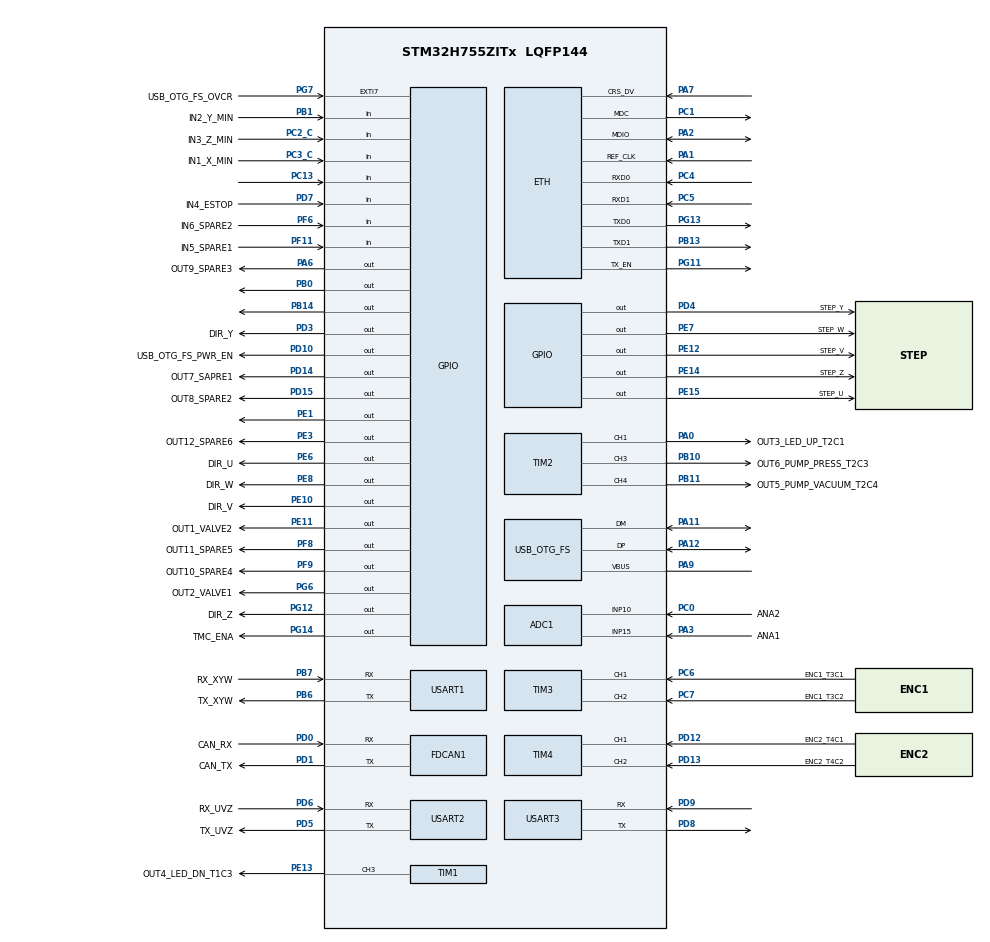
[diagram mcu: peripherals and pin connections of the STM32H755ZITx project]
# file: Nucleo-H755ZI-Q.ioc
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ADC1.Channel-0\#ChannelRegularConversion=ADC_CHANNEL_10
ADC1.NbrOfConversionFlag=1
ADC1.OffsetNumber-0\#ChannelRegularConversion=ADC_OFFSET_NONE
ADC1.OffsetSignedSaturation-0\#ChannelRegularConversion=DISABLE
ADC1.Rank-0\#ChannelRegularConversion=1
ADC1.SamplingTime-0\#ChannelRegularConversion=ADC_SAMPLETIME_1CYCLE_5
ADC1.master=1
CortexM4.IPs=FATFS_M4\:I,FREERTOS_M4\:I,IWDG2\:I,RCC,WWDG2\:I,DMA,BDMA,MDMA,NVIC2\:I,DEBUG,PDM2PCM_M4\:I,PWR,RESMGR_UTILITY,SYS_M4\:I,USB_DEVICE_M4\:I,USB_HOST_M4\:I,CORTEX_M4\:I,GPIO,OPENAMP_M4\:I,VREFBUF,NUCLEO-H755ZI-Q
CortexM7.IPs=FATFS_M7\:I,FREERTOS_M7\:I,IWDG1\:I,RCC\:I,WWDG1\:I,DMA\:I,BDMA\:I,MDMA\:I,NVIC1\:I,ETH\:I,USART3\:I,SYS\:I,CORTEX_M7\:I,DEBUG\:I,PDM2PCM_M7\:I,PWR\:I,RESMGR_UTILITY\:I,USB_DEVICE_M7\:I,USB_HOST_M7\:I,GPIO\:I,OPENAMP_M7\:I,VREFBUF\:I,NUCLEO-H755ZI-Q\:I,TIM1\:I,ADC3\:I,USB_OTG_FS\:I,LWIP\:I,TIM17\:I,FDCAN1\:I,USART2\:I,ADC1\:I,USART1\:I,TIM2\:I,TIM3\:I,TIM4\:I
CortexM7.Pins=PE3,PE6,PC13,PF6,PF8,PF9,PC2_C,PC3_C,PA6,PB1,PF11,PE7,PE8,PE10,PE11,PE12,PE14,PE15,PB14,PD10,PD14,PD15,PG6,PG7,PD3,PD4,PD7,PG12,PG14,PE1
ETH.MediaInterface=HAL_ETH_RMII_MODE
FDCAN1.CalculateBaudRateNominal=1000000
FDCAN1.CalculateTimeBitNominal=1000
FDCAN1.CalculateTimeQuantumNominal=200.0
FREERTOS_M7.Tasks01=defaultTask,24,512,StartDefaultTask,Default,NULL,Dynamic,NULL,NULL
FREERTOS_M7.configENABLE_FPU=1
FREERTOS_M7.configMINIMAL_STACK_SIZE=512
FREERTOS_M7.configUSE_NEWLIB_REENTRANT=1
LWIP.BSP.number=1
LWIP.Version=v2.1.2_Cube
LWIP0.BSP.STBoard=false
LWIP0.BSP.api=BSP_COMPONENT_DRIVER
LWIP0.BSP.component=LAN8742
LWIP0.BSP.instance=LAN8742
LWIP0.BSP.name=Driver_PHY
LWIP0.BSP.semaphore=S_LAN8742
LWIP0.BSP.solution=LAN8742
Mcu.Family=STM32H7
Mcu.Name=STM32H755ZITx
Mcu.Package=LQFP144
NUCLEO-H755ZI-Q.Bsp_Common_DEMO=true
NUCLEO-H755ZI-Q.LD1=true
NVIC1.ETH_IRQn=true\:5\:0\:false\:false\:true\:true\:true\:true\:true
NVIC1.OTG_FS_IRQn=true\:5\:0\:false\:false\:true\:true\:false\:true\:true
NVIC1.PriorityGroup=NVIC_PRIORITYGROUP_4
NVIC1.TIM17_IRQn=true\:15\:0\:false\:false\:true\:false\:false\:true\:true
NVIC1.TimeBase=TIM17_IRQn
NVIC1.TimeBaseIP=TIM17
NVIC2.PriorityGroup=NVIC_PRIORITYGROUP_4
PA0.GPIO_Label=OUT3_LED_UP_T2C1
PA0.PinAttribute=CortexM7
PA0.Signal=S_TIM2_CH1_ETR
PA1.Mode=RMII
PA1.PinAttribute=CortexM7
PA1.Signal=ETH_REF_CLK
PA11.Mode=Device_Only
PA11.PinAttribute=CortexM7
PA11.Signal=USB_OTG_FS_DM
PA12.Mode=Device_Only
PA12.PinAttribute=CortexM7
PA12.Signal=USB_OTG_FS_DP
PA2.Mode=RMII
PA2.PinAttribute=CortexM7
PA2.Signal=ETH_MDIO
PA3.GPIO_Label=ANA1
PA3.PinAttribute=CortexM7
PA3.Signal=ADCx_INP15
PA6.GPIO_Label=OUT9_SPARE3
PA6.PinAttribute=CortexM7
PA6.Signal=GPIO_Output
PA7.Mode=RMII
PA7.PinAttribute=CortexM7
PA7.Signal=ETH_CRS_DV
PA8.PinAttribute=CortexM7
PA8.Signal=USB_OTG_FS_SOF
PA9.Mode=Activate_VBUS
PA9.PinAttribute=CortexM7
PA9.Signal=USB_OTG_FS_VBUS
PB0.Signal=GPIO_Output
PB1.GPIO_Label=IN2_Y_MIN
PB1.PinAttribute=CortexM7
PB1.Signal=GPIO_Input
PB10.GPIO_Label=OUT6_PUMP_PRESS_T2C3
PB10.PinAttribute=CortexM7
PB10.Signal=S_TIM2_CH3
PB11.GPIO_Label=OUT5_PUMP_VACUUM_T2C4
PB11.PinAttribute=CortexM7
PB11.Signal=S_TIM2_CH4
PB13.Mode=RMII
PB13.PinAttribute=CortexM7
PB13.Signal=ETH_TXD1
PB14.PinAttribute=CortexM7
PB14.Signal=GPIO_Output
PB6.GPIO_Label=TX_XYW
PB6.Mode=Asynchronous
PB6.PinAttribute=CortexM7
PB6.Signal=USART1_TX
PB7.GPIO_Label=RX_XYW
PB7.Mode=Asynchronous
PB7.PinAttribute=CortexM7
PB7.Signal=USART1_RX
PC0.GPIO_Label=ANA2
PC0.PinAttribute=CortexM7
PC0.Signal=ADCx_INP10
PC1.Mode=RMII
PC1.PinAttribute=CortexM7
PC1.Signal=ETH_MDC
PC13.PinAttribute=CortexM7
PC13.Signal=GPIO_Input
PC14-OSC32_IN\ (OSC32_IN).PinAttribute=Free
PC14-OSC32_IN\ (OSC32_IN).Signal=RCC_OSC32_IN
PC15-OSC32_OUT\ (OSC32_OUT).PinAttribute=Free
PC15-OSC32_OUT\ (OSC32_OUT).Signal=RCC_OSC32_OUT
PC2_C.GPIO_Label=IN3_Z_MIN
PC2_C.PinAttribute=CortexM7
PC2_C.Signal=GPIO_Input
PC3_C.GPIO_Label=IN1_X_MIN
PC3_C.PinAttribute=CortexM7
PC3_C.Signal=GPIO_Input
PC4.Mode=RMII
PC4.PinAttribute=CortexM7
PC4.Signal=ETH_RXD0
PC5.Mode=RMII
PC5.PinAttribute=CortexM7
PC5.Signal=ETH_RXD1
PC6.GPIO_Label=ENC1_T3C1
PC6.PinAttribute=CortexM7
PC6.Signal=S_TIM3_CH1
PC7.GPIO_Label=ENC1_T3C2
PC7.PinAttribute=CortexM7
PC7.Signal=S_TIM3_CH2
PD0.GPIO_Label=CAN_RX
PD0.Mode=FDCAN_Activate
PD0.PinAttribute=CortexM7
PD0.Signal=FDCAN1_RX
PD1.GPIO_Label=CAN_TX
PD1.Mode=FDCAN_Activate
PD1.PinAttribute=CortexM7
PD1.Signal=FDCAN1_TX
PD10.GPIO_Label=USB_OTG_FS_PWR_EN
PD10.PinAttribute=CortexM7
PD10.Signal=GPIO_Output
PD12.GPIO_Label=ENC2_T4C1
PD12.PinAttribute=CortexM7
PD12.Signal=S_TIM4_CH1
PD13.GPIO_Label=ENC2_T4C2
PD13.PinAttribute=CortexM7
PD13.Signal=S_TIM4_CH2
PD14.GPIO_Label=OUT7_SAPRE1
PD14.PinAttribute=CortexM7
PD14.Signal=GPIO_Output
PD15.GPIO_Label=OUT8_SPARE2
PD15.PinAttribute=CortexM7
PD15.Signal=GPIO_Output
PD3.GPIO_Label=DIR_Y
PD3.PinAttribute=CortexM7
PD3.Signal=GPIO_Output
PD4.GPIO_Label=STEP_Y
PD4.PinAttribute=CortexM7
PD4.Signal=GPIO_Output
PD5.GPIO_Label=TX_UVZ
PD5.Mode=Asynchronous
PD5.PinAttribute=CortexM7
PD5.Signal=USART2_TX
PD6.GPIO_Label=RX_UVZ
PD6.Mode=Asynchronous
PD6.PinAttribute=CortexM7
PD6.Signal=USART2_RX
PD7.GPIO_Label=IN4_ESTOP
PD7.PinAttribute=CortexM7
PD7.Signal=GPIO_Input
PD8.Mode=Asynchronous
PD8.PinAttribute=CortexM7
PD8.Signal=USART3_TX
PD9.Mode=Asynchronous
PD9.PinAttribute=CortexM7
PD9.Signal=USART3_RX
PE1.PinAttribute=CortexM7
PE1.Signal=GPIO_Output
PE10.GPIO_Label=DIR_V
PE10.PinAttribute=CortexM7
PE10.Signal=GPIO_Output
PE11.GPIO_Label=OUT1_VALVE2
PE11.PinAttribute=CortexM7
PE11.Signal=GPIO_Output
PE12.GPIO_Label=STEP_V
PE12.PinAttribute=CortexM7
PE12.Signal=GPIO_Output
PE13.GPIO_Label=OUT4_LED_DN_T1C3
PE13.PinAttribute=CortexM7
PE13.Signal=S_TIM1_CH3
PE14.GPIO_Label=STEP_Z
PE14.PinAttribute=CortexM7
PE14.Signal=GPIO_Output
PE15.GPIO_Label=STEP_U
PE15.PinAttribute=CortexM7
PE15.Signal=GPIO_Output
PE3.GPIO_Label=OUT12_SPARE6
PE3.PinAttribute=CortexM7
PE3.Signal=GPIO_Output
PE6.GPIO_Label=DIR_U
PE6.PinAttribute=CortexM7
PE6.Signal=GPIO_Output
PE7.GPIO_Label=STEP_W
PE7.PinAttribute=CortexM7
PE7.Signal=GPIO_Output
PE8.GPIO_Label=DIR_W
PE8.PinAttribute=CortexM7
PE8.Signal=GPIO_Output
PF11.GPIO_Label=IN5_SPARE1
PF11.PinAttribute=CortexM7
PF11.Signal=GPIO_Input
PF6.GPIO_Label=IN6_SPARE2
PF6.PinAttribute=CortexM7
PF6.Signal=GPIO_Input
PF8.GPIO_Label=OUT11_SPARE5
PF8.PinAttribute=CortexM7
PF8.Signal=GPIO_Output
PF9.GPIO_Label=OUT10_SPARE4
PF9.PinAttribute=CortexM7
PF9.Signal=GPIO_Output
PG11.Mode=RMII
PG11.PinAttribute=CortexM7
PG11.Signal=ETH_TX_EN
PG12.GPIO_Label=DIR_Z
PG12.PinAttribute=CortexM7
PG12.Signal=GPIO_Output
PG13.Mode=RMII
PG13.PinAttribute=CortexM7
PG13.Signal=ETH_TXD0
PG14.GPIO_Label=TMC_ENA
PG14.PinAttribute=CortexM7
PG14.Signal=GPIO_Output
PG6.GPIO_Label=OUT2_VALVE1
PG6.PinAttribute=CortexM7
PG6.Signal=GPIO_Output
PG7.GPIO_Label=USB_OTG_FS_OVCR
PG7.PinAttribute=CortexM7
PG7.Signal=GPXTI7
PH0-OSC_IN\ (PH0).Mode=HSE-External-Clock-Source
PH0-OSC_IN\ (PH0).PinAttribute=Free
PH0-OSC_IN\ (PH0).Signal=RCC_OSC_IN
PH1-OSC_OUT\ (PH1).PinAttribute=Free
PH1-OSC_OUT\ (PH1).Signal=RCC_OSC_OUT
ProjectManager.HeapSize=M4-0x200,M7-0x200
ProjectManager.StackSize=M4-0x400,M7-0x400
ProjectManager.TargetToolchain=STM32CubeIDE
RCC.ADCFreq_Value=80000000
RCC.APB1Freq_Value=120000000
RCC.APB2Freq_Value=120000000
RCC.APB3Freq_Value=120000000
RCC.APB4Freq_Value=120000000
RCC.CortexFreq_Value=480000000
RCC.D1PPRE=RCC_APB3_DIV2
RCC.D2PPRE1=RCC_APB1_DIV2
RCC.D2PPRE2=RCC_APB2_DIV2
RCC.D3PPRE=RCC_APB4_DIV2
RCC.DIVM1=1
RCC.DIVM2=1
RCC.DIVM3=1
RCC.DIVN1=120
RCC.DIVN2=20
RCC.DIVN3=24
RCC.DIVQ1=3
RCC.DIVQ3=4
RCC.FDCANCLockSelection=RCC_FDCANCLKSOURCE_PLL2
RCC.HCLKFreq_Value=240000000
RCC.HPRE=RCC_HCLK_DIV2
RCC.HSE_VALUE=8000000
RCC.PLL2FRACN=0
RCC.PLL3FRACN=0
RCC.PLLFRACN=0
RCC.PLLSourceVirtual=RCC_PLLSOURCE_HSE
RCC.SYSCLKFreq_VALUE=480000000
RCC.SYSCLKSource=RCC_SYSCLKSOURCE_PLLCLK
RCC.SupplySource=PWR_LDO_SUPPLY
RCC.USBCLockSelection=RCC_USBCLKSOURCE_PLL3
RCC.USBFreq_Value=48000000
SH.ADCx_INP10.0=ADC1_INP10,IN10-Single-Ended
SH.ADCx_INP15.0=ADC1_INP15,IN15-Single-Ended
SH.S_TIM1_CH3.0=TIM1_CH3,PWM Generation3 CH3
SH.S_TIM2_CH1_ETR.0=TIM2_CH1,PWM Generation1 CH1
SH.S_TIM2_CH3.0=TIM2_CH3,PWM Generation3 CH3
SH.S_TIM2_CH4.0=TIM2_CH4,PWM Generation4 CH4
SH.S_TIM3_CH1.0=TIM3_CH1,Encoder_Interface
SH.S_TIM3_CH2.0=TIM3_CH2,Encoder_Interface
SH.S_TIM4_CH1.0=TIM4_CH1,Encoder_Interface
SH.S_TIM4_CH2.0=TIM4_CH2,Encoder_Interface
TIM1.Channel-PWM\ Generation3\ CH3=TIM_CHANNEL_3
TIM2.Channel-PWM\ Generation1\ CH1=TIM_CHANNEL_1
TIM2.Channel-PWM\ Generation3\ CH3=TIM_CHANNEL_3
TIM2.Channel-PWM\ Generation4\ CH4=TIM_CHANNEL_4
USART1.VirtualMode-Asynchronous=VM_ASYNC
USART2.VirtualMode-Asynchronous=VM_ASYNC
USART3.VirtualMode-Asynchronous=VM_ASYNC
USB_DEVICE_M7.CLASS_NAME_FS=CDC
USB_DEVICE_M7.VirtualMode-CDC_FS=Cdc
USB_DEVICE_M7.VirtualModeFS=Cdc_FS
USB_OTG_FS.VirtualMode=Device_Only
VP_FREERTOS_M7_VS_CMSIS_V2.Mode=CMSIS_V2
VP_LWIP_VS_Enabled.Mode=Enabled
VP_NUCLEO-H755ZI-Q_VS_BSP_COMMON.Mode=COMMON
VP_SYS_M4_VS_Systick.Mode=SysTick
VP_SYS_VS_tim17.Mode=TIM17
VP_TIM1_VS_ClockSourceINT.Mode=Internal
VP_TIM2_VS_ClockSourceINT.Mode=Internal
VP_USB_DEVICE_M7_VS_USB_DEVICE_CDC_FS.Mode=CDC_FS
board=NUCLEO-H755ZI-Q

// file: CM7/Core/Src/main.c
/* USER CODE BEGIN Header */
/**
  ******************************************************************************
  * @file           : main.c
  * @brief          : Main program body
  ******************************************************************************
  * @attention
  *
  * Copyright (c) 2025 STMicroelectronics.
  * All rights reserved.
  *
  * This software is licensed under terms that can be found in the LICENSE file
  * in the root directory of this software component.
  * If no LICENSE file comes with this software, it is provided AS-IS.
  *
  ******************************************************************************
  */
/* USER CODE END Header */
#include "main.h"
#include "cmsis_os.h"
#include "lwip.h"
#include "usb_device.h"

/* USER CODE BEGIN PD */

#ifndef HSEM_ID_0
#define HSEM_ID_0 (0U) /* HW semaphore 0*/
#endif

/* USER CODE END PD */

__IO uint32_t BspButtonState = BUTTON_RELEASED;
ADC_HandleTypeDef hadc1;

FDCAN_HandleTypeDef hfdcan1;

TIM_HandleTypeDef htim1;
TIM_HandleTypeDef htim2;
TIM_HandleTypeDef htim3;
TIM_HandleTypeDef htim4;

UART_HandleTypeDef huart1;
UART_HandleTypeDef huart2;
UART_HandleTypeDef huart3;

/* Definitions for defaultTask */
osThreadId_t defaultTaskHandle;
const osThreadAttr_t defaultTask_attributes = {
  .name = "defaultTask",
  .stack_size = 512 * 4,
  .priority = (osPriority_t) osPriorityNormal,
};

void SystemClock_Config(void);
void PeriphCommonClock_Config(void);
static void MX_GPIO_Init(void);
static void MX_TIM1_Init(void);
static void MX_ADC1_Init(void);
static void MX_FDCAN1_Init(void);
static void MX_USART2_UART_Init(void);
static void MX_USART3_UART_Init(void);
static void MX_TIM2_Init(void);
static void MX_TIM3_Init(void);
static void MX_TIM4_Init(void);
static void MX_USART1_UART_Init(void);
void StartDefaultTask(void *argument);

int main(void)
{

/* USER CODE BEGIN Boot_Mode_Sequence_0 */
  int32_t timeout;
/* USER CODE END Boot_Mode_Sequence_0 */

/* USER CODE BEGIN Boot_Mode_Sequence_1 */
  /* Wait until CPU2 boots and enters in stop mode or timeout*/
  timeout = 0xFFFF;
  while((__HAL_RCC_GET_FLAG(RCC_FLAG_D2CKRDY) != RESET) && (timeout-- > 0));
  if ( timeout < 0 )
  {
  Error_Handler();
  }
/* USER CODE END Boot_Mode_Sequence_1 */
  /* MCU Configuration--------------------------------------------------------*/

  /* Reset of all peripherals, Initializes the Flash interface and the Systick. */
  HAL_Init();

  /* Configure the system clock */
  SystemClock_Config();

  /* Configure the peripherals common clocks */
  PeriphCommonClock_Config();
/* USER CODE BEGIN Boot_Mode_Sequence_2 */
/* When system initialization is finished, Cortex-M7 will release Cortex-M4 by means of
HSEM notification */
/*HW semaphore Clock enable*/
__HAL_RCC_HSEM_CLK_ENABLE();
/*Take HSEM */
HAL_HSEM_FastTake(HSEM_ID_0);
/*Release HSEM in order to notify the CPU2(CM4)*/
HAL_HSEM_Release(HSEM_ID_0,0);
/* wait until CPU2 wakes up from stop mode */
timeout = 0xFFFF;
while((__HAL_RCC_GET_FLAG(RCC_FLAG_D2CKRDY) == RESET) && (timeout-- > 0));
if ( timeout < 0 )
{
Error_Handler();
}
/* USER CODE END Boot_Mode_Sequence_2 */

  /* Initialize all configured peripherals */
  MX_GPIO_Init();
  MX_TIM1_Init();
  MX_ADC1_Init();
  MX_FDCAN1_Init();
  MX_USART2_UART_Init();
  MX_USART3_UART_Init();
  MX_TIM2_Init();
  MX_TIM3_Init();
  MX_TIM4_Init();
  MX_USART1_UART_Init();

  /* Init scheduler */
  osKernelInitialize();

  /* Create the thread(s) */
  /* creation of defaultTask */
  defaultTaskHandle = osThreadNew(StartDefaultTask, NULL, &defaultTask_attributes);

  /* Initialize leds */
  BSP_LED_Init(LED_GREEN);

  /* USER CODE BEGIN BSP */
  /* -- Sample board code to switch on leds ---- */
  BSP_LED_On(LED_GREEN);
  /* USER CODE END BSP */

  /* Start scheduler */
  osKernelStart();

  /* We should never get here as control is now taken by the scheduler */

  /* Infinite loop */
  while (1)
  {

  }
}

void SystemClock_Config(void)
{
  RCC_OscInitTypeDef RCC_OscInitStruct = {0};
  RCC_ClkInitTypeDef RCC_ClkInitStruct = {0};

  /** Supply configuration update enable
  */
  HAL_PWREx_ConfigSupply(PWR_LDO_SUPPLY);

  /** Configure the main internal regulator output voltage
  */
  __HAL_PWR_VOLTAGESCALING_CONFIG(PWR_REGULATOR_VOLTAGE_SCALE1);

  while(!__HAL_PWR_GET_FLAG(PWR_FLAG_VOSRDY)) {}

  __HAL_RCC_SYSCFG_CLK_ENABLE();
  __HAL_PWR_VOLTAGESCALING_CONFIG(PWR_REGULATOR_VOLTAGE_SCALE0);

  while(!__HAL_PWR_GET_FLAG(PWR_FLAG_VOSRDY)) {}

  /** Initializes the RCC Oscillators according to the specified parameters
  * in the RCC_OscInitTypeDef structure.
  */
  RCC_OscInitStruct.OscillatorType = RCC_OSCILLATORTYPE_HSE;
  RCC_OscInitStruct.HSEState = RCC_HSE_BYPASS;
  RCC_OscInitStruct.PLL.PLLState = RCC_PLL_ON;
  RCC_OscInitStruct.PLL.PLLSource = RCC_PLLSOURCE_HSE;
  RCC_OscInitStruct.PLL.PLLM = 1;
  RCC_OscInitStruct.PLL.PLLN = 120;
  RCC_OscInitStruct.PLL.PLLP = 2;
  RCC_OscInitStruct.PLL.PLLQ = 3;
  RCC_OscInitStruct.PLL.PLLR = 2;
  RCC_OscInitStruct.PLL.PLLRGE = RCC_PLL1VCIRANGE_3;
  RCC_OscInitStruct.PLL.PLLVCOSEL = RCC_PLL1VCOWIDE;
  RCC_OscInitStruct.PLL.PLLFRACN = 0;
  if (HAL_RCC_OscConfig(&RCC_OscInitStruct) != HAL_OK)
  {
    Error_Handler();
  }

  /** Initializes the CPU, AHB and APB buses clocks
  */
  RCC_ClkInitStruct.ClockType = RCC_CLOCKTYPE_HCLK|RCC_CLOCKTYPE_SYSCLK
                              |RCC_CLOCKTYPE_PCLK1|RCC_CLOCKTYPE_PCLK2
                              |RCC_CLOCKTYPE_D3PCLK1|RCC_CLOCKTYPE_D1PCLK1;
  RCC_ClkInitStruct.SYSCLKSource = RCC_SYSCLKSOURCE_PLLCLK;
  RCC_ClkInitStruct.SYSCLKDivider = RCC_SYSCLK_DIV1;
  RCC_ClkInitStruct.AHBCLKDivider = RCC_HCLK_DIV2;
  RCC_ClkInitStruct.APB3CLKDivider = RCC_APB3_DIV2;
  RCC_ClkInitStruct.APB1CLKDivider = RCC_APB1_DIV2;
  RCC_ClkInitStruct.APB2CLKDivider = RCC_APB2_DIV2;
  RCC_ClkInitStruct.APB4CLKDivider = RCC_APB4_DIV2;

  if (HAL_RCC_ClockConfig(&RCC_ClkInitStruct, FLASH_LATENCY_4) != HAL_OK)
  {
    Error_Handler();
  }
}

void PeriphCommonClock_Config(void)
{
  RCC_PeriphCLKInitTypeDef PeriphClkInitStruct = {0};

  /** Initializes the peripherals clock
  */
  PeriphClkInitStruct.PeriphClockSelection = RCC_PERIPHCLK_ADC|RCC_PERIPHCLK_FDCAN;
  PeriphClkInitStruct.PLL2.PLL2M = 1;
  PeriphClkInitStruct.PLL2.PLL2N = 20;
  PeriphClkInitStruct.PLL2.PLL2P = 2;
  PeriphClkInitStruct.PLL2.PLL2Q = 2;
  PeriphClkInitStruct.PLL2.PLL2R = 2;
  PeriphClkInitStruct.PLL2.PLL2RGE = RCC_PLL2VCIRANGE_3;
  PeriphClkInitStruct.PLL2.PLL2VCOSEL = RCC_PLL2VCOMEDIUM;
  PeriphClkInitStruct.PLL2.PLL2FRACN = 0;
  PeriphClkInitStruct.FdcanClockSelection = RCC_FDCANCLKSOURCE_PLL2;
  PeriphClkInitStruct.AdcClockSelection = RCC_ADCCLKSOURCE_PLL2;
  if (HAL_RCCEx_PeriphCLKConfig(&PeriphClkInitStruct) != HAL_OK)
  {
    Error_Handler();
  }
}

static void MX_ADC1_Init(void)
{

  ADC_MultiModeTypeDef multimode = {0};
  ADC_ChannelConfTypeDef sConfig = {0};

  /** Common config
  */
  hadc1.Instance = ADC1;
  hadc1.Init.ScanConvMode = ADC_SCAN_DISABLE;
  hadc1.Init.EOCSelection = ADC_EOC_SINGLE_CONV;
  hadc1.Init.LowPowerAutoWait = DISABLE;
  hadc1.Init.ContinuousConvMode = DISABLE;
  hadc1.Init.NbrOfConversion = 1;
  hadc1.Init.DiscontinuousConvMode = DISABLE;
  hadc1.Init.ExternalTrigConv = ADC_SOFTWARE_START;
  hadc1.Init.ExternalTrigConvEdge = ADC_EXTERNALTRIGCONVEDGE_NONE;
  hadc1.Init.ConversionDataManagement = ADC_CONVERSIONDATA_DR;
  hadc1.Init.Overrun = ADC_OVR_DATA_PRESERVED;
  hadc1.Init.LeftBitShift = ADC_LEFTBITSHIFT_NONE;
  hadc1.Init.OversamplingMode = DISABLE;
  hadc1.Init.Oversampling.Ratio = 1;
  if (HAL_ADC_Init(&hadc1) != HAL_OK)
  {
    Error_Handler();
  }
  hadc1.Init.ClockPrescaler = ADC_CLOCK_ASYNC_DIV1;
  hadc1.Init.Resolution = ADC_RESOLUTION_16B;
  if (HAL_ADC_Init(&hadc1) != HAL_OK)
  {
    Error_Handler();
  }

  /** Configure the ADC multi-mode
  */
  multimode.Mode = ADC_MODE_INDEPENDENT;
  if (HAL_ADCEx_MultiModeConfigChannel(&hadc1, &multimode) != HAL_OK)
  {
    Error_Handler();
  }

  /** Configure Regular Channel
  */
  sConfig.Channel = ADC_CHANNEL_10;
  sConfig.Rank = ADC_REGULAR_RANK_1;
  sConfig.SamplingTime = ADC_SAMPLETIME_1CYCLE_5;
  sConfig.SingleDiff = ADC_SINGLE_ENDED;
  sConfig.OffsetNumber = ADC_OFFSET_NONE;
  sConfig.Offset = 0;
  sConfig.OffsetSignedSaturation = DISABLE;
  if (HAL_ADC_ConfigChannel(&hadc1, &sConfig) != HAL_OK)
  {
    Error_Handler();
  }

}

static void MX_FDCAN1_Init(void)
{

  hfdcan1.Instance = FDCAN1;
  hfdcan1.Init.FrameFormat = FDCAN_FRAME_CLASSIC;
  hfdcan1.Init.Mode = FDCAN_MODE_NORMAL;
  hfdcan1.Init.AutoRetransmission = DISABLE;
  hfdcan1.Init.TransmitPause = DISABLE;
  hfdcan1.Init.ProtocolException = DISABLE;
  hfdcan1.Init.NominalPrescaler = 16;
  hfdcan1.Init.NominalSyncJumpWidth = 1;
  hfdcan1.Init.NominalTimeSeg1 = 2;
  hfdcan1.Init.NominalTimeSeg2 = 2;
  hfdcan1.Init.DataPrescaler = 1;
  hfdcan1.Init.DataSyncJumpWidth = 1;
  hfdcan1.Init.DataTimeSeg1 = 1;
  hfdcan1.Init.DataTimeSeg2 = 1;
  hfdcan1.Init.MessageRAMOffset = 0;
  hfdcan1.Init.StdFiltersNbr = 0;
  hfdcan1.Init.ExtFiltersNbr = 0;
  hfdcan1.Init.RxFifo0ElmtsNbr = 0;
  hfdcan1.Init.RxFifo0ElmtSize = FDCAN_DATA_BYTES_8;
  hfdcan1.Init.RxFifo1ElmtsNbr = 0;
  hfdcan1.Init.RxFifo1ElmtSize = FDCAN_DATA_BYTES_8;
  hfdcan1.Init.RxBuffersNbr = 0;
  hfdcan1.Init.RxBufferSize = FDCAN_DATA_BYTES_8;
  hfdcan1.Init.TxEventsNbr = 0;
  hfdcan1.Init.TxBuffersNbr = 0;
  hfdcan1.Init.TxFifoQueueElmtsNbr = 0;
  hfdcan1.Init.TxFifoQueueMode = FDCAN_TX_FIFO_OPERATION;
  hfdcan1.Init.TxElmtSize = FDCAN_DATA_BYTES_8;
  if (HAL_FDCAN_Init(&hfdcan1) != HAL_OK)
  {
    Error_Handler();
  }

}

static void MX_TIM1_Init(void)
{

  TIM_ClockConfigTypeDef sClockSourceConfig = {0};
  TIM_MasterConfigTypeDef sMasterConfig = {0};
  TIM_OC_InitTypeDef sConfigOC = {0};
  TIM_BreakDeadTimeConfigTypeDef sBreakDeadTimeConfig = {0};

  htim1.Instance = TIM1;
  htim1.Init.Prescaler = 0;
  htim1.Init.CounterMode = TIM_COUNTERMODE_UP;
  htim1.Init.Period = 65535;
  htim1.Init.ClockDivision = TIM_CLOCKDIVISION_DIV1;
  htim1.Init.RepetitionCounter = 0;
  htim1.Init.AutoReloadPreload = TIM_AUTORELOAD_PRELOAD_DISABLE;
  if (HAL_TIM_Base_Init(&htim1) != HAL_OK)
  {
    Error_Handler();
  }
  sClockSourceConfig.ClockSource = TIM_CLOCKSOURCE_INTERNAL;
  if (HAL_TIM_ConfigClockSource(&htim1, &sClockSourceConfig) != HAL_OK)
  {
    Error_Handler();
  }
  if (HAL_TIM_PWM_Init(&htim1) != HAL_OK)
  {
    Error_Handler();
  }
  sMasterConfig.MasterOutputTrigger = TIM_TRGO_RESET;
  sMasterConfig.MasterOutputTrigger2 = TIM_TRGO2_RESET;
  sMasterConfig.MasterSlaveMode = TIM_MASTERSLAVEMODE_DISABLE;
  if (HAL_TIMEx_MasterConfigSynchronization(&htim1, &sMasterConfig) != HAL_OK)
  {
    Error_Handler();
  }
  sConfigOC.OCMode = TIM_OCMODE_PWM1;
  sConfigOC.Pulse = 0;
  sConfigOC.OCPolarity = TIM_OCPOLARITY_HIGH;
  sConfigOC.OCNPolarity = TIM_OCNPOLARITY_HIGH;
  sConfigOC.OCFastMode = TIM_OCFAST_DISABLE;
  sConfigOC.OCIdleState = TIM_OCIDLESTATE_RESET;
  sConfigOC.OCNIdleState = TIM_OCNIDLESTATE_RESET;
  if (HAL_TIM_PWM_ConfigChannel(&htim1, &sConfigOC, TIM_CHANNEL_3) != HAL_OK)
  {
    Error_Handler();
  }
  sBreakDeadTimeConfig.OffStateRunMode = TIM_OSSR_DISABLE;
  sBreakDeadTimeConfig.OffStateIDLEMode = TIM_OSSI_DISABLE;
  sBreakDeadTimeConfig.LockLevel = TIM_LOCKLEVEL_OFF;
  sBreakDeadTimeConfig.DeadTime = 0;
  sBreakDeadTimeConfig.BreakState = TIM_BREAK_DISABLE;
  sBreakDeadTimeConfig.BreakPolarity = TIM_BREAKPOLARITY_HIGH;
  sBreakDeadTimeConfig.BreakFilter = 0;
  sBreakDeadTimeConfig.Break2State = TIM_BREAK2_DISABLE;
  sBreakDeadTimeConfig.Break2Polarity = TIM_BREAK2POLARITY_HIGH;
  sBreakDeadTimeConfig.Break2Filter = 0;
  sBreakDeadTimeConfig.AutomaticOutput = TIM_AUTOMATICOUTPUT_DISABLE;
  if (HAL_TIMEx_ConfigBreakDeadTime(&htim1, &sBreakDeadTimeConfig) != HAL_OK)
  {
    Error_Handler();
  }
  HAL_TIM_MspPostInit(&htim1);

}

static void MX_TIM2_Init(void)
{

  TIM_ClockConfigTypeDef sClockSourceConfig = {0};
  TIM_MasterConfigTypeDef sMasterConfig = {0};
  TIM_OC_InitTypeDef sConfigOC = {0};

  htim2.Instance = TIM2;
  htim2.Init.Prescaler = 0;
  htim2.Init.CounterMode = TIM_COUNTERMODE_UP;
  htim2.Init.Period = 4294967295;
  htim2.Init.ClockDivision = TIM_CLOCKDIVISION_DIV1;
  htim2.Init.AutoReloadPreload = TIM_AUTORELOAD_PRELOAD_DISABLE;
  if (HAL_TIM_Base_Init(&htim2) != HAL_OK)
  {
    Error_Handler();
  }
  sClockSourceConfig.ClockSource = TIM_CLOCKSOURCE_INTERNAL;
  if (HAL_TIM_ConfigClockSource(&htim2, &sClockSourceConfig) != HAL_OK)
  {
    Error_Handler();
  }
  if (HAL_TIM_PWM_Init(&htim2) != HAL_OK)
  {
    Error_Handler();
  }
  sMasterConfig.MasterOutputTrigger = TIM_TRGO_RESET;
  sMasterConfig.MasterSlaveMode = TIM_MASTERSLAVEMODE_DISABLE;
  if (HAL_TIMEx_MasterConfigSynchronization(&htim2, &sMasterConfig) != HAL_OK)
  {
    Error_Handler();
  }
  sConfigOC.OCMode = TIM_OCMODE_PWM1;
  sConfigOC.Pulse = 0;
  sConfigOC.OCPolarity = TIM_OCPOLARITY_HIGH;
  sConfigOC.OCFastMode = TIM_OCFAST_DISABLE;
  if (HAL_TIM_PWM_ConfigChannel(&htim2, &sConfigOC, TIM_CHANNEL_1) != HAL_OK)
  {
    Error_Handler();
  }
  if (HAL_TIM_PWM_ConfigChannel(&htim2, &sConfigOC, TIM_CHANNEL_3) != HAL_OK)
  {
    Error_Handler();
  }
  if (HAL_TIM_PWM_ConfigChannel(&htim2, &sConfigOC, TIM_CHANNEL_4) != HAL_OK)
  {
    Error_Handler();
  }
  HAL_TIM_MspPostInit(&htim2);

}

static void MX_TIM3_Init(void)
{

  TIM_Encoder_InitTypeDef sConfig = {0};
  TIM_MasterConfigTypeDef sMasterConfig = {0};

  htim3.Instance = TIM3;
  htim3.Init.Prescaler = 0;
  htim3.Init.CounterMode = TIM_COUNTERMODE_UP;
  htim3.Init.Period = 65535;
  htim3.Init.ClockDivision = TIM_CLOCKDIVISION_DIV1;
  htim3.Init.AutoReloadPreload = TIM_AUTORELOAD_PRELOAD_DISABLE;
  sConfig.EncoderMode = TIM_ENCODERMODE_TI1;
  sConfig.IC1Polarity = TIM_ICPOLARITY_RISING;
  sConfig.IC1Selection = TIM_ICSELECTION_DIRECTTI;
  sConfig.IC1Prescaler = TIM_ICPSC_DIV1;
  sConfig.IC1Filter = 0;
  sConfig.IC2Polarity = TIM_ICPOLARITY_RISING;
  sConfig.IC2Selection = TIM_ICSELECTION_DIRECTTI;
  sConfig.IC2Prescaler = TIM_ICPSC_DIV1;
  sConfig.IC2Filter = 0;
  if (HAL_TIM_Encoder_Init(&htim3, &sConfig) != HAL_OK)
  {
    Error_Handler();
  }
  sMasterConfig.MasterOutputTrigger = TIM_TRGO_RESET;
  sMasterConfig.MasterSlaveMode = TIM_MASTERSLAVEMODE_DISABLE;
  if (HAL_TIMEx_MasterConfigSynchronization(&htim3, &sMasterConfig) != HAL_OK)
  {
    Error_Handler();
  }

}

static void MX_TIM4_Init(void)
{

  TIM_Encoder_InitTypeDef sConfig = {0};
  TIM_MasterConfigTypeDef sMasterConfig = {0};

  htim4.Instance = TIM4;
  htim4.Init.Prescaler = 0;
  htim4.Init.CounterMode = TIM_COUNTERMODE_UP;
  htim4.Init.Period = 65535;
  htim4.Init.ClockDivision = TIM_CLOCKDIVISION_DIV1;
  htim4.Init.AutoReloadPreload = TIM_AUTORELOAD_PRELOAD_DISABLE;
  sConfig.EncoderMode = TIM_ENCODERMODE_TI1;
  sConfig.IC1Polarity = TIM_ICPOLARITY_RISING;
  sConfig.IC1Selection = TIM_ICSELECTION_DIRECTTI;
  sConfig.IC1Prescaler = TIM_ICPSC_DIV1;
  sConfig.IC1Filter = 0;
  sConfig.IC2Polarity = TIM_ICPOLARITY_RISING;
  sConfig.IC2Selection = TIM_ICSELECTION_DIRECTTI;
  sConfig.IC2Prescaler = TIM_ICPSC_DIV1;
  sConfig.IC2Filter = 0;
  if (HAL_TIM_Encoder_Init(&htim4, &sConfig) != HAL_OK)
  {
    Error_Handler();
  }
  sMasterConfig.MasterOutputTrigger = TIM_TRGO_RESET;
  sMasterConfig.MasterSlaveMode = TIM_MASTERSLAVEMODE_DISABLE;
  if (HAL_TIMEx_MasterConfigSynchronization(&htim4, &sMasterConfig) != HAL_OK)
  {
    Error_Handler();
  }

}

static void MX_USART1_UART_Init(void)
{

  huart1.Instance = USART1;
  huart1.Init.BaudRate = 115200;
  huart1.Init.WordLength = UART_WORDLENGTH_8B;
  huart1.Init.StopBits = UART_STOPBITS_1;
  huart1.Init.Parity = UART_PARITY_NONE;
  huart1.Init.Mode = UART_MODE_TX_RX;
  huart1.Init.HwFlowCtl = UART_HWCONTROL_NONE;
  huart1.Init.OverSampling = UART_OVERSAMPLING_16;
  huart1.Init.OneBitSampling = UART_ONE_BIT_SAMPLE_DISABLE;
  huart1.Init.ClockPrescaler = UART_PRESCALER_DIV1;
  huart1.AdvancedInit.AdvFeatureInit = UART_ADVFEATURE_NO_INIT;
  if (HAL_UART_Init(&huart1) != HAL_OK)
  {
    Error_Handler();
  }
  if (HAL_UARTEx_SetTxFifoThreshold(&huart1, UART_TXFIFO_THRESHOLD_1_8) != HAL_OK)
  {
    Error_Handler();
  }
  if (HAL_UARTEx_SetRxFifoThreshold(&huart1, UART_RXFIFO_THRESHOLD_1_8) != HAL_OK)
  {
    Error_Handler();
  }
  if (HAL_UARTEx_DisableFifoMode(&huart1) != HAL_OK)
  {
    Error_Handler();
  }

}

static void MX_USART2_UART_Init(void)
{

  huart2.Instance = USART2;
  huart2.Init.BaudRate = 115200;
  huart2.Init.WordLength = UART_WORDLENGTH_8B;
  huart2.Init.StopBits = UART_STOPBITS_1;
  huart2.Init.Parity = UART_PARITY_NONE;
  huart2.Init.Mode = UART_MODE_TX_RX;
  huart2.Init.HwFlowCtl = UART_HWCONTROL_NONE;
  huart2.Init.OverSampling = UART_OVERSAMPLING_16;
  huart2.Init.OneBitSampling = UART_ONE_BIT_SAMPLE_DISABLE;
  huart2.Init.ClockPrescaler = UART_PRESCALER_DIV1;
  huart2.AdvancedInit.AdvFeatureInit = UART_ADVFEATURE_NO_INIT;
  if (HAL_UART_Init(&huart2) != HAL_OK)
  {
    Error_Handler();
  }
  if (HAL_UARTEx_SetTxFifoThreshold(&huart2, UART_TXFIFO_THRESHOLD_1_8) != HAL_OK)
  {
    Error_Handler();
  }
  if (HAL_UARTEx_SetRxFifoThreshold(&huart2, UART_RXFIFO_THRESHOLD_1_8) != HAL_OK)
  {
    Error_Handler();
  }
  if (HAL_UARTEx_DisableFifoMode(&huart2) != HAL_OK)
  {
    Error_Handler();
  }

}

static void MX_USART3_UART_Init(void)
{

  huart3.Instance = USART3;
  huart3.Init.BaudRate = 115200;
  huart3.Init.WordLength = UART_WORDLENGTH_8B;
  huart3.Init.StopBits = UART_STOPBITS_1;
  huart3.Init.Parity = UART_PARITY_NONE;
  huart3.Init.Mode = UART_MODE_TX_RX;
  huart3.Init.HwFlowCtl = UART_HWCONTROL_NONE;
  huart3.Init.OverSampling = UART_OVERSAMPLING_16;
  huart3.Init.OneBitSampling = UART_ONE_BIT_SAMPLE_DISABLE;
  huart3.Init.ClockPrescaler = UART_PRESCALER_DIV1;
  huart3.AdvancedInit.AdvFeatureInit = UART_ADVFEATURE_NO_INIT;
  if (HAL_UART_Init(&huart3) != HAL_OK)
  {
    Error_Handler();
  }
  if (HAL_UARTEx_SetTxFifoThreshold(&huart3, UART_TXFIFO_THRESHOLD_1_8) != HAL_OK)
  {
    Error_Handler();
  }
  if (HAL_UARTEx_SetRxFifoThreshold(&huart3, UART_RXFIFO_THRESHOLD_1_8) != HAL_OK)
  {
    Error_Handler();
  }
  if (HAL_UARTEx_DisableFifoMode(&huart3) != HAL_OK)
  {
    Error_Handler();
  }

}

static void MX_GPIO_Init(void)
{
  GPIO_InitTypeDef GPIO_InitStruct = {0};

  /* GPIO Ports Clock Enable */
  __HAL_RCC_GPIOE_CLK_ENABLE();
  __HAL_RCC_GPIOC_CLK_ENABLE();
  __HAL_RCC_GPIOF_CLK_ENABLE();
  __HAL_RCC_GPIOA_CLK_ENABLE();
  __HAL_RCC_GPIOB_CLK_ENABLE();
  __HAL_RCC_GPIOD_CLK_ENABLE();
  __HAL_RCC_GPIOG_CLK_ENABLE();

  /*Configure GPIO pin Output Level */
  HAL_GPIO_WritePin(GPIOE, OUT12_SPARE6_Pin|DIR_U_Pin|STEP_W_Pin|DIR_W_Pin
                          |DIR_V_Pin|OUT1_VALVE2_Pin|STEP_V_Pin|STEP_Z_Pin
                          |STEP_U_Pin|GPIO_PIN_1, GPIO_PIN_RESET);

  /*Configure GPIO pin Output Level */
  HAL_GPIO_WritePin(GPIOF, OUT11_SPARE5_Pin|OUT10_SPARE4_Pin, GPIO_PIN_RESET);

  /*Configure GPIO pin Output Level */
  HAL_GPIO_WritePin(OUT9_SPARE3_GPIO_Port, OUT9_SPARE3_Pin, GPIO_PIN_RESET);

  /*Configure GPIO pin Output Level */
  HAL_GPIO_WritePin(GPIOB, GPIO_PIN_14, GPIO_PIN_RESET);

  /*Configure GPIO pin Output Level */
  HAL_GPIO_WritePin(GPIOD, USB_OTG_FS_PWR_EN_Pin|OUT7_SAPRE1_Pin|OUT8_SPARE2_Pin|DIR_Y_Pin
                          |STEP_Y_Pin, GPIO_PIN_RESET);

  /*Configure GPIO pin Output Level */
  HAL_GPIO_WritePin(GPIOG, OUT2_VALVE1_Pin|DIR_Z_Pin|TMC_ENA_Pin, GPIO_PIN_RESET);

  /*Configure GPIO pins : OUT12_SPARE6_Pin DIR_U_Pin STEP_W_Pin DIR_W_Pin
                           DIR_V_Pin OUT1_VALVE2_Pin STEP_V_Pin STEP_Z_Pin
                           STEP_U_Pin PE1 */
  GPIO_InitStruct.Pin = OUT12_SPARE6_Pin|DIR_U_Pin|STEP_W_Pin|DIR_W_Pin
                          |DIR_V_Pin|OUT1_VALVE2_Pin|STEP_V_Pin|STEP_Z_Pin
                          |STEP_U_Pin|GPIO_PIN_1;
  GPIO_InitStruct.Mode = GPIO_MODE_OUTPUT_PP;
  GPIO_InitStruct.Pull = GPIO_NOPULL;
  GPIO_InitStruct.Speed = GPIO_SPEED_FREQ_LOW;
  HAL_GPIO_Init(GPIOE, &GPIO_InitStruct);

  /*Configure GPIO pins : PC13 IN3_Z_MIN_Pin IN1_X_MIN_Pin */
  GPIO_InitStruct.Pin = GPIO_PIN_13|IN3_Z_MIN_Pin|IN1_X_MIN_Pin;
  GPIO_InitStruct.Mode = GPIO_MODE_INPUT;
  GPIO_InitStruct.Pull = GPIO_NOPULL;
  HAL_GPIO_Init(GPIOC, &GPIO_InitStruct);

  /*Configure GPIO pins : IN6_SPARE2_Pin IN5_SPARE1_Pin */
  GPIO_InitStruct.Pin = IN6_SPARE2_Pin|IN5_SPARE1_Pin;
  GPIO_InitStruct.Mode = GPIO_MODE_INPUT;
  GPIO_InitStruct.Pull = GPIO_NOPULL;
  HAL_GPIO_Init(GPIOF, &GPIO_InitStruct);

  /*Configure GPIO pins : OUT11_SPARE5_Pin OUT10_SPARE4_Pin */
  GPIO_InitStruct.Pin = OUT11_SPARE5_Pin|OUT10_SPARE4_Pin;
  GPIO_InitStruct.Mode = GPIO_MODE_OUTPUT_PP;
  GPIO_InitStruct.Pull = GPIO_NOPULL;
  GPIO_InitStruct.Speed = GPIO_SPEED_FREQ_LOW;
  HAL_GPIO_Init(GPIOF, &GPIO_InitStruct);

  /*Configure GPIO pin : OUT9_SPARE3_Pin */
  GPIO_InitStruct.Pin = OUT9_SPARE3_Pin;
  GPIO_InitStruct.Mode = GPIO_MODE_OUTPUT_PP;
  GPIO_InitStruct.Pull = GPIO_NOPULL;
  GPIO_InitStruct.Speed = GPIO_SPEED_FREQ_LOW;
  HAL_GPIO_Init(OUT9_SPARE3_GPIO_Port, &GPIO_InitStruct);

  /*Configure GPIO pin : IN2_Y_MIN_Pin */
  GPIO_InitStruct.Pin = IN2_Y_MIN_Pin;
  GPIO_InitStruct.Mode = GPIO_MODE_INPUT;
  GPIO_InitStruct.Pull = GPIO_NOPULL;
  HAL_GPIO_Init(IN2_Y_MIN_GPIO_Port, &GPIO_InitStruct);

  /*Configure GPIO pin : PB14 */
  GPIO_InitStruct.Pin = GPIO_PIN_14;
  GPIO_InitStruct.Mode = GPIO_MODE_OUTPUT_PP;
  GPIO_InitStruct.Pull = GPIO_NOPULL;
  GPIO_InitStruct.Speed = GPIO_SPEED_FREQ_LOW;
  HAL_GPIO_Init(GPIOB, &GPIO_InitStruct);

  /*Configure GPIO pins : USB_OTG_FS_PWR_EN_Pin OUT7_SAPRE1_Pin OUT8_SPARE2_Pin DIR_Y_Pin
                           STEP_Y_Pin */
  GPIO_InitStruct.Pin = USB_OTG_FS_PWR_EN_Pin|OUT7_SAPRE1_Pin|OUT8_SPARE2_Pin|DIR_Y_Pin
                          |STEP_Y_Pin;
  GPIO_InitStruct.Mode = GPIO_MODE_OUTPUT_PP;
  GPIO_InitStruct.Pull = GPIO_NOPULL;
  GPIO_InitStruct.Speed = GPIO_SPEED_FREQ_LOW;
  HAL_GPIO_Init(GPIOD, &GPIO_InitStruct);

  /*Configure GPIO pins : OUT2_VALVE1_Pin DIR_Z_Pin TMC_ENA_Pin */
  GPIO_InitStruct.Pin = OUT2_VALVE1_Pin|DIR_Z_Pin|TMC_ENA_Pin;
  GPIO_InitStruct.Mode = GPIO_MODE_OUTPUT_PP;
  GPIO_InitStruct.Pull = GPIO_NOPULL;
  GPIO_InitStruct.Speed = GPIO_SPEED_FREQ_LOW;
  HAL_GPIO_Init(GPIOG, &GPIO_InitStruct);

  /*Configure GPIO pin : USB_OTG_FS_OVCR_Pin */
  GPIO_InitStruct.Pin = USB_OTG_FS_OVCR_Pin;
  GPIO_InitStruct.Mode = GPIO_MODE_IT_RISING;
  GPIO_InitStruct.Pull = GPIO_NOPULL;
  HAL_GPIO_Init(USB_OTG_FS_OVCR_GPIO_Port, &GPIO_InitStruct);

  /*Configure GPIO pin : IN4_ESTOP_Pin */
  GPIO_InitStruct.Pin = IN4_ESTOP_Pin;
  GPIO_InitStruct.Mode = GPIO_MODE_INPUT;
  GPIO_InitStruct.Pull = GPIO_NOPULL;
  HAL_GPIO_Init(IN4_ESTOP_GPIO_Port, &GPIO_InitStruct);

}

void StartDefaultTask(void *argument)
{
  /* init code for LWIP */
  MX_LWIP_Init();

  /* init code for USB_DEVICE */
  MX_USB_DEVICE_Init();
  for(;;)
  {
    osDelay(1);
  }
}

void HAL_TIM_PeriodElapsedCallback(TIM_HandleTypeDef *htim)
{
  if (htim->Instance == TIM17) {
    HAL_IncTick();
  }
}

void Error_Handler(void)
{
  __disable_irq();
  while (1)
  {
  }
}
